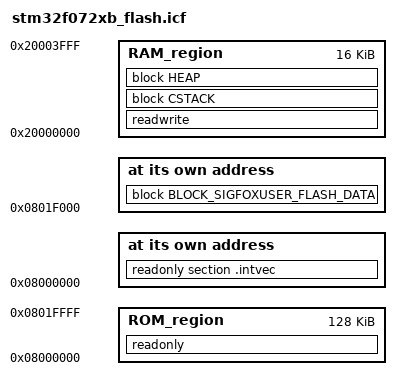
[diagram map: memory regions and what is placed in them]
/*###ICF### Section handled by ICF editor, don't touch! ****/
/*-Editor annotation file-*/
/* IcfEditorFile="$TOOLKIT_DIR$\config\ide\IcfEditor\cortex_v1_0.xml" */
/*-Specials-*/
define symbol __ICFEDIT_intvec_start__ = 0x08000000;
/*-Memory Regions-*/
define symbol __ICFEDIT_region_ROM_start__ = 0x08000000;
define symbol __ICFEDIT_region_ROM_end__   = 0x0801FFFF;
define symbol __ICFEDIT_region_RAM_start__ = 0x20000000;
define symbol __ICFEDIT_region_RAM_end__   = 0x20003FFF;
/*-Sizes-*/
define symbol __ICFEDIT_size_cstack__ = 0x400;
define symbol __ICFEDIT_size_heap__   = 0x200;
/**** End of ICF editor section. ###ICF###*/

define symbol FLASH_NVM_DATASIZE = 2*2048;

define memory mem with size = 4G;
define region ROM_region   = mem:[from __ICFEDIT_region_ROM_start__   to __ICFEDIT_region_ROM_end__];
define region RAM_region   = mem:[from __ICFEDIT_region_RAM_start__   to __ICFEDIT_region_RAM_end__];

define block CSTACK    with alignment = 8, size = __ICFEDIT_size_cstack__   { };
define block HEAP      with alignment = 8, size = __ICFEDIT_size_heap__     { };

initialize by copy { readwrite };
do not initialize  { section .noinit };

place at address mem:__ICFEDIT_intvec_start__ { readonly section .intvec };

place in ROM_region   { readonly };
place in RAM_region   { readwrite,
                        block CSTACK, block HEAP };

export symbol __ICFEDIT_region_RAM_start__;
export symbol __ICFEDIT_region_RAM_end__;

/*******************************************************************************
* Sigfox Data Sections
*******************************************************************************/
/**
* Here are stored Sigfox information and recurrent data.
*/
define block BLOCK_SIGFOXUSER_FLASH_DATA with alignment = 2048, fixed order, size = FLASH_NVM_DATASIZE
{
    section .noinit.sigfox_board_data,
    section .noinit.sigfox_nvm_data
};
place at address mem: 0x0801F000 {block BLOCK_SIGFOXUSER_FLASH_DATA};
do not initialize { section .noinit.sigfox_board_data,
                    section .noinit.sigfox_nvm_data};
